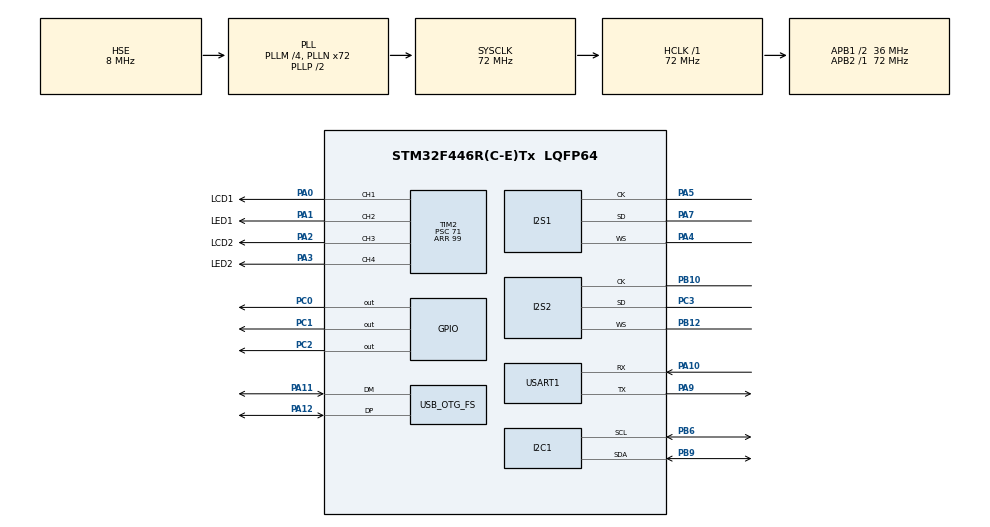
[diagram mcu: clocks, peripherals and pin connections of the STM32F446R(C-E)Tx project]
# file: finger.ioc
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Dma.Request0=SPI1_RX
Dma.Request1=SPI2_RX
Dma.SPI1_RX.0.Direction=DMA_PERIPH_TO_MEMORY
Dma.SPI1_RX.0.FIFOMode=DMA_FIFOMODE_DISABLE
Dma.SPI1_RX.0.Instance=DMA2_Stream0
Dma.SPI1_RX.0.MemDataAlignment=DMA_MDATAALIGN_WORD
Dma.SPI1_RX.0.MemInc=DMA_MINC_ENABLE
Dma.SPI1_RX.0.Mode=DMA_CIRCULAR
Dma.SPI1_RX.0.PeriphDataAlignment=DMA_PDATAALIGN_WORD
Dma.SPI1_RX.0.PeriphInc=DMA_PINC_DISABLE
Dma.SPI1_RX.0.Priority=DMA_PRIORITY_LOW
Dma.SPI2_RX.1.Direction=DMA_PERIPH_TO_MEMORY
Dma.SPI2_RX.1.FIFOMode=DMA_FIFOMODE_DISABLE
Dma.SPI2_RX.1.Instance=DMA1_Stream3
Dma.SPI2_RX.1.MemDataAlignment=DMA_MDATAALIGN_WORD
Dma.SPI2_RX.1.MemInc=DMA_MINC_ENABLE
Dma.SPI2_RX.1.Mode=DMA_CIRCULAR
Dma.SPI2_RX.1.PeriphDataAlignment=DMA_PDATAALIGN_WORD
Dma.SPI2_RX.1.PeriphInc=DMA_PINC_DISABLE
Dma.SPI2_RX.1.Priority=DMA_PRIORITY_LOW
I2C1.I2C_Mode=I2C_Fast
I2S1.AudioFreq=I2S_AUDIOFREQ_48K
I2S1.DataFormat=I2S_DATAFORMAT_24B
I2S1.ErrorAudioFreq=0.0 %
I2S1.FullDuplexMode=I2S_FULLDUPLEXMODE_DISABLE
I2S1.Instance=SPI$Index
I2S1.Mode=I2S_MODE_MASTER_RX
I2S1.RealAudioFreq=48.0 KHz
I2S1.VirtualMode=I2S_MODE_MASTER
I2S2.AudioFreq=I2S_AUDIOFREQ_48K
I2S2.DataFormat=I2S_DATAFORMAT_24B
I2S2.ErrorAudioFreq=0.0 %
I2S2.FullDuplexMode=I2S_FULLDUPLEXMODE_DISABLE
I2S2.Instance=SPI$Index
I2S2.Mode=I2S_MODE_MASTER_RX
I2S2.RealAudioFreq=48.0 KHz
I2S2.VirtualMode=I2S_MODE_MASTER
Mcu.Family=STM32F4
Mcu.Name=STM32F446R(C-E)Tx
Mcu.Package=LQFP64
NVIC.DMA1_Stream3_IRQn=true\:5\:0\:true\:false\:true\:false\:true\:true
NVIC.DMA2_Stream0_IRQn=true\:5\:0\:true\:false\:true\:false\:true\:true
NVIC.OTG_FS_IRQn=true\:1\:0\:true\:false\:true\:false\:true\:true
NVIC.PriorityGroup=NVIC_PRIORITYGROUP_4
PA0-WKUP.GPIO_Label=LCD1
PA0-WKUP.Signal=S_TIM2_CH1_ETR
PA1.GPIO_Label=LED1
PA1.Signal=S_TIM2_CH2
PA10.Mode=Asynchronous
PA10.Signal=USART1_RX
PA11.Mode=Device_Only
PA11.Signal=USB_OTG_FS_DM
PA12.Mode=Device_Only
PA12.Signal=USB_OTG_FS_DP
PA13.Mode=Serial_Wire
PA13.Signal=SYS_JTMS-SWDIO
PA14.Mode=Serial_Wire
PA14.Signal=SYS_JTCK-SWCLK
PA2.GPIO_Label=LCD2
PA2.Signal=S_TIM2_CH3
PA3.GPIO_Label=LED2
PA3.Signal=S_TIM2_CH4
PA4.GPIO_Mode=GPIO_MODE_AF_PP
PA4.GPIO_PuPd=GPIO_NOPULL
PA4.GPIO_Speed=GPIO_SPEED_FREQ_LOW
PA4.Mode=Half_Duplex_Master
PA4.Signal=I2S1_WS
PA5.GPIO_Mode=GPIO_MODE_AF_PP
PA5.GPIO_PuPd=GPIO_NOPULL
PA5.GPIO_Speed=GPIO_SPEED_FREQ_LOW
PA5.Mode=Half_Duplex_Master
PA5.Signal=I2S1_CK
PA7.GPIO_Mode=GPIO_MODE_AF_PP
PA7.GPIO_PuPd=GPIO_NOPULL
PA7.GPIO_Speed=GPIO_SPEED_FREQ_LOW
PA7.Mode=Half_Duplex_Master
PA7.Signal=I2S1_SD
PA9.Mode=Asynchronous
PA9.Signal=USART1_TX
PB10.Mode=Half_Duplex_Master
PB10.Signal=I2S2_CK
PB12.Mode=Half_Duplex_Master
PB12.Signal=I2S2_WS
PB6.Mode=I2C
PB6.Signal=I2C1_SCL
PB9.Mode=I2C
PB9.Signal=I2C1_SDA
PC0.Signal=GPIO_Output
PC1.PinState=GPIO_PIN_RESET
PC1.Signal=GPIO_Output
PC2.PinState=GPIO_PIN_RESET
PC2.Signal=GPIO_Output
PC3.Mode=Half_Duplex_Master
PC3.Signal=I2S2_SD
PH0-OSC_IN.Mode=HSE-External-Oscillator
PH0-OSC_IN.Signal=RCC_OSC_IN
PH1-OSC_OUT.Mode=HSE-External-Oscillator
PH1-OSC_OUT.Signal=RCC_OSC_OUT
ProjectManager.HeapSize=0x1000
ProjectManager.StackSize=0x4000
ProjectManager.TargetToolchain=EWARM V8.50
RCC.AHBFreq_Value=72000000
RCC.APB1CLKDivider=RCC_HCLK_DIV2
RCC.APB1Freq_Value=36000000
RCC.APB1TimFreq_Value=72000000
RCC.APB2Freq_Value=72000000
RCC.APB2TimFreq_Value=72000000
RCC.CortexFreq_Value=72000000
RCC.HCLKFreq_Value=72000000
RCC.HSE_VALUE=8000000
RCC.PLLI2SM=4
RCC.PLLI2SN=192
RCC.PLLI2SR=5
RCC.PLLM=4
RCC.PLLN=72
RCC.PLLQ=3
RCC.PLLSourceVirtual=RCC_PLLSOURCE_HSE
RCC.SYSCLKFreq_VALUE=72000000
RCC.SYSCLKSource=RCC_SYSCLKSOURCE_PLLCLK
RCC.USBFreq_Value=48000000
RCC.VCOOutputFreq_Value=144000000
SH.S_TIM2_CH1_ETR.0=TIM2_CH1,PWM Generation1 CH1
SH.S_TIM2_CH2.0=TIM2_CH2,PWM Generation2 CH2
SH.S_TIM2_CH3.0=TIM2_CH3,PWM Generation3 CH3
SH.S_TIM2_CH4.0=TIM2_CH4,PWM Generation4 CH4
TIM2.Channel-PWM\ Generation1\ CH1=TIM_CHANNEL_1
TIM2.Channel-PWM\ Generation2\ CH2=TIM_CHANNEL_2
TIM2.Channel-PWM\ Generation3\ CH3=TIM_CHANNEL_3
TIM2.Channel-PWM\ Generation4\ CH4=TIM_CHANNEL_4
TIM2.Period=99
TIM2.Prescaler=71
USART1.VirtualMode=VM_ASYNC
USB_DEVICE.CLASS_NAME_FS=CDC
USB_DEVICE.VirtualMode-CDC_FS=Cdc
USB_DEVICE.VirtualModeFS=Cdc_FS
USB_OTG_FS.VirtualMode=Device_Only
VP_TIM2_VS_ClockSourceINT.Mode=Internal
VP_USB_DEVICE_VS_USB_DEVICE_CDC_FS.Mode=CDC_FS
board=custom

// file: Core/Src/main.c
/* USER CODE BEGIN Header */
/**
  ******************************************************************************
  * @file           : main.c
  * @brief          : Main program body
  ******************************************************************************
  * @attention
  *
  * Copyright (c) 2025 STMicroelectronics.
  * All rights reserved.
  *
  * This software is licensed under terms that can be found in the LICENSE file
  * in the root directory of this software component.
  * If no LICENSE file comes with this software, it is provided AS-IS.
  *
  ******************************************************************************
  */
/* USER CODE END Header */
#include "main.h"
#include "dma.h"
#include "i2c.h"
#include "i2s.h"
#include "tim.h"
#include "usart.h"
#include "usb_device.h"
#include "gpio.h"

/* USER CODE BEGIN Includes */
#include "my_application.h"
/* USER CODE END Includes */

void SystemClock_Config(void);
void PeriphCommonClock_Config(void);

int main(void)
{

  /* MCU Configuration--------------------------------------------------------*/

  /* Reset of all peripherals, Initializes the Flash interface and the Systick. */
  HAL_Init();

  /* Configure the system clock */
  SystemClock_Config();

  /* Configure the peripherals common clocks */
  PeriphCommonClock_Config();

  /* Initialize all configured peripherals */
  MX_GPIO_Init();
  MX_DMA_Init();
  MX_I2C1_Init();
  MX_USART1_UART_Init();
  MX_I2S1_Init();
  MX_USB_DEVICE_Init();
  MX_I2S2_Init();
  MX_TIM2_Init();
  /* USER CODE BEGIN 2 */

  // Initialize all sensors
  My_Application_Init();
  HAL_TIM_PWM_Start(&htim2, TIM_CHANNEL_1);
  HAL_TIM_PWM_Start(&htim2, TIM_CHANNEL_2);
  HAL_TIM_PWM_Start(&htim2, TIM_CHANNEL_3);
  HAL_TIM_PWM_Start(&htim2, TIM_CHANNEL_4);

  /* USER CODE END 2 */

  /* Infinite loop */

    /* USER CODE BEGIN 3 */
  // Run main sensor loop (never returns)
  My_Application_Run();

  /* USER CODE END 3 */
}

void SystemClock_Config(void)
{
  RCC_OscInitTypeDef RCC_OscInitStruct = {0};
  RCC_ClkInitTypeDef RCC_ClkInitStruct = {0};

  /** Configure the main internal regulator output voltage
  */
  __HAL_RCC_PWR_CLK_ENABLE();
  __HAL_PWR_VOLTAGESCALING_CONFIG(PWR_REGULATOR_VOLTAGE_SCALE3);

  /** Initializes the RCC Oscillators according to the specified parameters
  * in the RCC_OscInitTypeDef structure.
  */
  RCC_OscInitStruct.OscillatorType = RCC_OSCILLATORTYPE_HSE;
  RCC_OscInitStruct.HSEState = RCC_HSE_ON;
  RCC_OscInitStruct.PLL.PLLState = RCC_PLL_ON;
  RCC_OscInitStruct.PLL.PLLSource = RCC_PLLSOURCE_HSE;
  RCC_OscInitStruct.PLL.PLLM = 4;
  RCC_OscInitStruct.PLL.PLLN = 72;
  RCC_OscInitStruct.PLL.PLLP = RCC_PLLP_DIV2;
  RCC_OscInitStruct.PLL.PLLQ = 3;
  RCC_OscInitStruct.PLL.PLLR = 2;
  if (HAL_RCC_OscConfig(&RCC_OscInitStruct) != HAL_OK)
  {
    Error_Handler();
  }

  /** Initializes the CPU, AHB and APB buses clocks
  */
  RCC_ClkInitStruct.ClockType = RCC_CLOCKTYPE_HCLK|RCC_CLOCKTYPE_SYSCLK
                              |RCC_CLOCKTYPE_PCLK1|RCC_CLOCKTYPE_PCLK2;
  RCC_ClkInitStruct.SYSCLKSource = RCC_SYSCLKSOURCE_PLLCLK;
  RCC_ClkInitStruct.AHBCLKDivider = RCC_SYSCLK_DIV1;
  RCC_ClkInitStruct.APB1CLKDivider = RCC_HCLK_DIV2;
  RCC_ClkInitStruct.APB2CLKDivider = RCC_HCLK_DIV1;

  if (HAL_RCC_ClockConfig(&RCC_ClkInitStruct, FLASH_LATENCY_2) != HAL_OK)
  {
    Error_Handler();
  }
}

void PeriphCommonClock_Config(void)
{
  RCC_PeriphCLKInitTypeDef PeriphClkInitStruct = {0};

  /** Initializes the peripherals clock
  */
  PeriphClkInitStruct.PeriphClockSelection = RCC_PERIPHCLK_I2S_APB1|RCC_PERIPHCLK_I2S_APB2;
  PeriphClkInitStruct.PLLI2S.PLLI2SN = 192;
  PeriphClkInitStruct.PLLI2S.PLLI2SP = RCC_PLLI2SP_DIV2;
  PeriphClkInitStruct.PLLI2S.PLLI2SM = 4;
  PeriphClkInitStruct.PLLI2S.PLLI2SR = 5;
  PeriphClkInitStruct.PLLI2S.PLLI2SQ = 2;
  PeriphClkInitStruct.PLLI2SDivQ = 1;
  PeriphClkInitStruct.I2sApb2ClockSelection = RCC_I2SAPB2CLKSOURCE_PLLI2S;
  PeriphClkInitStruct.I2sApb1ClockSelection = RCC_I2SAPB1CLKSOURCE_PLLI2S;
  if (HAL_RCCEx_PeriphCLKConfig(&PeriphClkInitStruct) != HAL_OK)
  {
    Error_Handler();
  }
}

void Error_Handler(void)
{
  __disable_irq();
  while (1)
  {
  }
}
